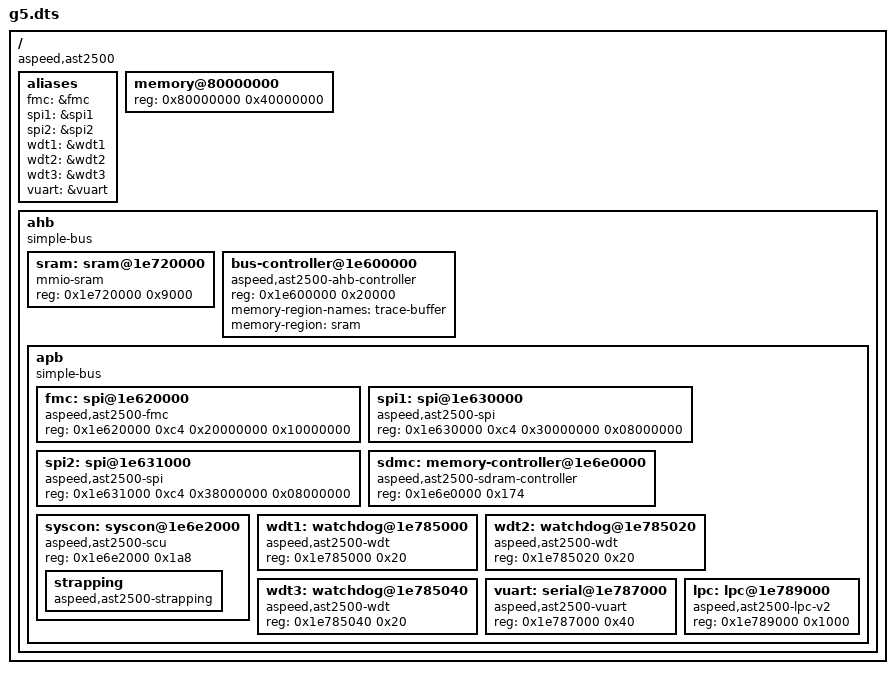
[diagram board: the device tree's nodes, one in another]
// SPDX-License-Identifier: Apache-2.0
// Copyright 2021 IBM Corp.

/dts-v1/;

/ {
	compatible = "aspeed,ast2500";
	#address-cells = <1>;
	#size-cells = <1>;

	aliases {
		fmc = &fmc;
		spi1 = &spi1;
		spi2 = &spi2;
		wdt1 = &wdt1;
		wdt2 = &wdt2;
		wdt3 = &wdt3;
		vuart = &vuart;
	};

	memory@80000000 {
		device_type = "memory";
		reg = <0x80000000 0x40000000>;
	};

	ahb {
		compatible = "simple-bus";
		#address-cells = <1>;
		#size-cells = <1>;
		ranges;

		sram: sram@1e720000 {
			compatible = "mmio-sram";
			reg = <0x1e720000 0x9000>;	// 36K
		};

		bus-controller@1e600000 {
			compatible = "aspeed,ast2500-ahb-controller";
			reg = <0x1e600000 0x20000>;

			memory-region-names = "trace-buffer";
			// Technically should point to a node under reserved-memory, but SRAM isn't
			// mapped anyway which is why we're using it.
			memory-region = <&sram>;
		};

		apb {
			compatible = "simple-bus";
			#address-cells = <1>;
			#size-cells = <1>;

			fmc: spi@1e620000 {
				reg = <0x1e620000 0xc4
				       0x20000000 0x10000000>;
				compatible = "aspeed,ast2500-fmc";
			};

			spi1: spi@1e630000 {
				reg = <0x1e630000 0xc4
				       0x30000000 0x08000000>;
				compatible = "aspeed,ast2500-spi";
			};

			spi2: spi@1e631000 {
				reg = <0x1e631000 0xc4
				       0x38000000 0x08000000>;
				compatible = "aspeed,ast2500-spi";
			};

			sdmc: memory-controller@1e6e0000 {
				compatible = "aspeed,ast2500-sdram-controller";
				reg = <0x1e6e0000 0x174>;
			};

			syscon: syscon@1e6e2000 {
				compatible = "aspeed,ast2500-scu", "syscon", "simple-mfd";
				reg = <0x1e6e2000 0x1a8>;

				strapping {
					compatible = "aspeed,ast2500-strapping";
				};
			};

			wdt1: watchdog@1e785000 {
				compatible = "aspeed,ast2500-wdt";
				reg = <0x1e785000 0x20>;
			};

			wdt2: watchdog@1e785020 {
				compatible = "aspeed,ast2500-wdt";
				reg = <0x1e785020 0x20>;
			};

			wdt3: watchdog@1e785040 {
				compatible = "aspeed,ast2500-wdt";
				reg = <0x1e785040 0x20>;
			};

			vuart: serial@1e787000 {
				compatible = "aspeed,ast2500-vuart";
				reg = <0x1e787000 0x40>;
			};

			lpc: lpc@1e789000 {
				compatible = "aspeed,ast2500-lpc-v2", "syscon", "simple-mfd";
				reg = <0x1e789000 0x1000>;
			};
		};
	};
};
